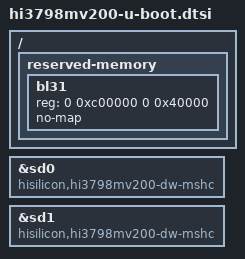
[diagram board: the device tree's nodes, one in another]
// SPDX-License-Identifier: GPL-2.0+
/*
 * U-Boot addition to:
 *  1) use platform data for the console
 *
 */

#include <dt-bindings/reset/ti-syscon.h>

/ {
	reserved-memory {
		#address-cells = <2>;
		#size-cells = <2>;
		ranges;

		bl31 {
			reg = <0 0xc00000 0 0x40000>;
			no-map;
		};
	};
};

/* The driver in U-Boot does not support "snps,dw-mshc" compatible. */
&sd0 {
	compatible = "hisilicon,hi3798mv200-dw-mshc";
};

&sd1 {
	compatible = "hisilicon,hi3798mv200-dw-mshc";
};
